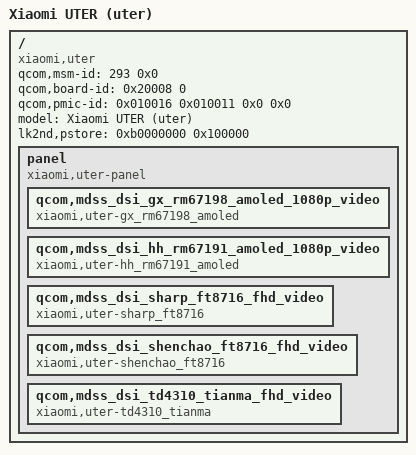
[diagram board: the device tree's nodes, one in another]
// SPDX-License-Identifier: GPL-2.0-only

/dts-v1/;

/include/ "msm8953.dtsi"

/ {
	// This is used by the bootloader to find the correct DTB
	qcom,msm-id = <293 0x0>;
	qcom,board-id = <0x20008 0>;
	qcom,pmic-id = <0x010016 0x010011 0x0 0x0>;

	model = "Xiaomi UTER (uter)";
	compatible = "xiaomi,uter", "qcom,msm8953", "lk2nd,device";
	lk2nd,pstore = <0xb0000000 0x100000>;

	panel {
		compatible = "xiaomi,uter-panel";

		qcom,mdss_dsi_gx_rm67198_amoled_1080p_video {
			compatible = "xiaomi,uter-gx_rm67198_amoled";
		};
		qcom,mdss_dsi_hh_rm67191_amoled_1080p_video {
			compatible = "xiaomi,uter-hh_rm67191_amoled";
		};
		qcom,mdss_dsi_sharp_ft8716_fhd_video {
			compatible = "xiaomi,uter-sharp_ft8716";
		};
		qcom,mdss_dsi_shenchao_ft8716_fhd_video {
			compatible = "xiaomi,uter-shenchao_ft8716";
		};
		qcom,mdss_dsi_td4310_tianma_fhd_video {
			compatible = "xiaomi,uter-td4310_tianma";
		};
	};
};
